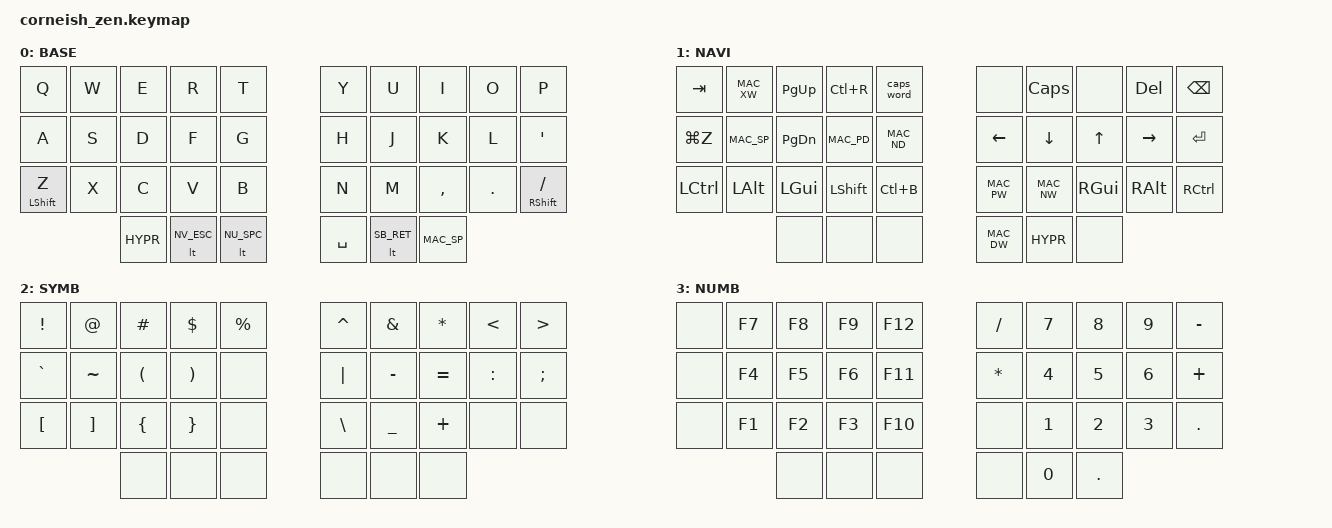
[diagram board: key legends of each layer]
#include <behaviors.dtsi>
#include <dt-bindings/zmk/keys.h>
#include <dt-bindings/zmk/bt.h>

// Layer aliases
#define BASE   0
#define NAVI   1
#define SYMB   2
#define NUMB   3
// Layer toggle aliases
#define NU_SPC NUMB SPACE
#define NV_ESC NAVI ESC
#define SB_RET SYMB RET
// Shortcuts
#define HYPR   LG(LS(LA(LCTRL)))
#define MAC_DW LA(BKSP)
#define MAC_SP LG(SPACE)
#define MAC_NW LA(RIGHT)
#define MAC_PW LA(LEFT)
#define MAC_XW LG(GRAVE)
#define MAC_PD LC(LEFT)
#define MAC_ND LC(RIGHT)

/ {
  chosen {
    // zmk,matrix_transform = &default_transform;
    zmk,matrix_transform = &five_column_transform;
  };
};

// Key index
// 0  1  2  3  4    5  6  7  8  9
// 10 11 12 13 14   15 16 17 18 19
// 20 21 22 23 24   25 26 27 28 29
//       30 31 32   33 34 35

/ {
    combos {
        compatible = "zmk,combos";

        combo_save {
            timeout-ms = <50>;
            key-positions = <1 11>;
            bindings = <&kp LG(S)>;
        };
        // This doesn't work for some reason, seems like
        // edge keys can't be combo'd
        combo_undo {
            timeout-ms = <50>;
            key-positions = <10 20>;
            bindings = <&kp LG(X)>;
        };
        combo_cut {
            timeout-ms = <50>;
            key-positions = <11 21>;
            bindings = <&kp LG(X)>;
        };
        combo_copy {
            timeout-ms = <50>;
            key-positions = <12 22>;
            bindings = <&kp LG(C)>;
        };
        combo_undo {
            timeout-ms = <50>;
            key-positions = <13 23>;
            bindings = <&kp LG(V)>;
        };
    };
};

/ {
        keymap {
                compatible = "zmk,keymap";

                default_layer {
                        label = "BASE";
                        bindings = <
   &kp Q       &kp W &kp E &kp R &kp T      &kp Y &kp U  &kp I     &kp O   &kp P
   &kp A       &kp S &kp D &kp F &kp G      &kp H &kp J  &kp K     &kp L   &kp SQT
   &mt LSHFT Z &kp X &kp C &kp V &kp B      &kp N &kp M  &kp COMMA &kp DOT &mt RSHFT FSLH
        &kp HYPR &lt NV_ESC &lt NU_SPC      &kp SPACE &lt SB_RET &kp MAC_SP
                        >;
                };
                navigation_layer {
                        label = "NAVI";
                        bindings = <
   &kp TAB   &kp MAC_XW &kp PG_UP &kp LC(R)  &caps_word      &none      &kp CAPS   &none    &kp DEL   &kp BSPC
   &kp LG(Z) &kp MAC_SP &kp PG_DN &kp MAC_PD &kp MAC_ND      &kp LEFT   &kp DOWN   &kp UP   &kp RIGHT &kp RET
   &kp LCTRL &kp LALT   &kp LGUI  &kp LSHFT  &kp LC(B)       &kp MAC_PW &kp MAC_NW &kp RGUI &kp RALT  &kp RCTRL
                        &none     &none      &none           &kp MAC_DW &kp HYPR   &none
                        >;
                };
                symbol_layer {
                        label = "SYMB";
                        bindings = <
   &kp EXCL  &kp AT    &kp HASH &kp DLLR &kp PRCNT      &kp CARET &kp AMPS  &kp ASTRK &kp LT    &kp GT
   &kp GRAVE &kp TILDE &kp LPAR &kp RPAR &none          &kp PIPE  &kp MINUS &kp EQUAL &kp COLON &kp SEMI
   &kp LBKT  &kp RBKT  &kp LBRC &kp RBRC &none          &kp BSLH  &kp UNDER &kp PLUS  &none     &none
                       &none    &none    &none          &none     &none     &none
                        >;
                };
                number_layer {
                        label = "NUMB";
                        bindings = <
   &none &kp F7 &kp F8 &kp F9 &kp F12      &kp SLASH &kp N7 &kp N8 &kp N9 &kp MINUS
   &none &kp F4 &kp F5 &kp F6 &kp F11      &kp ASTRK &kp N4 &kp N5 &kp N6 &kp PLUS
   &none &kp F1 &kp F2 &kp F3 &kp F10      &none     &kp N1 &kp N2 &kp N3 &kp DOT
                &none  &none  &none        &none     &kp N0 &kp DOT
                        >;
                };
        };
};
